# MDR1986VK214 register map
Vendor: Milandr; Series: ARMCM0; File version: 2.0
CPU: CM0 r0p0, little endian, no MPU, no FPU, 2 interrupt priority bits
Registers are 32-bit, read-write, reset 0x0 unless marked. A register's access mark holds for its fields unless they carry their own. Offsets are from the block's base; [hi:lo] are bit positions; {n}, {i} and the like mark numbered series; 'fields as' and 'values as' point back to an identical list.

## MDR_RST_CLOCK — CLock Control
Base 0x40020000
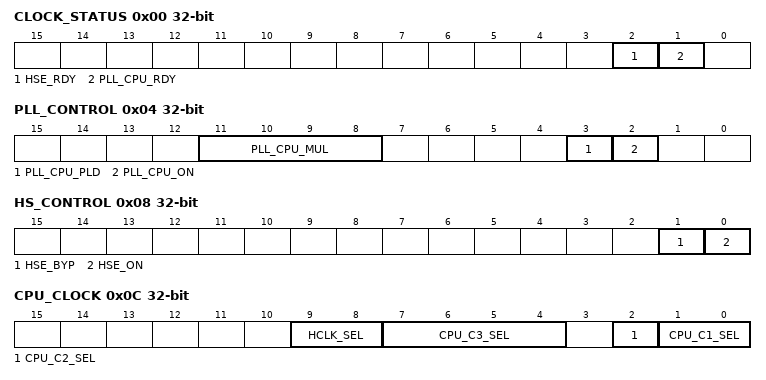
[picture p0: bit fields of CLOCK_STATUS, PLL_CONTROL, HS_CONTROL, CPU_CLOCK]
0x00 CLOCK_STATUS ro
  [2] HSE_RDY — HSE generator ready
    0=NotReady (HSE not ready); 1=Ready (HSE ready)
  [1] PLL_CPU_RDY — PLL CPU ready
    0=NotReady (PLL not ready); 1=Ready (PLL ready)
0x04 PLL_CONTROL (reset mask 0x20C)
  [11:8] PLL_CPU_MUL — PLL CPU Mul, [x1 .. x16]
    0=PLL mul x1; {v}=x{v+1} (PLL mul x{v+1}) (v=1..8); 9=PLL mul x10; 10=PLL mul x11; {v}=x{v+1} (PLL mul x{v+1}) (v=11..15)
  [3] PLL_CPU_PLD — PLL CPU Restart
    0=RestartOff (PLL restart inactive); 1=DoRestart (PLL Do Restart)
  [2] PLL_CPU_ON — PLL CPU Enable
    0=Off (PLL Off); 1=On (PLL On)
0x08 HS_CONTROL — HSE Generator Control
  [1] HSE_BYP — HSE Bypass Mode
    0=Off (HSE forms Clock from external oscillator); 1=On (HSE passes Clock from external generator)
  [0] HSE_ON — HSE Enable
    0=Off (HSE Off); 1=On (HSE On)
0x0C CPU_CLOCK — CPU Clock Control
  [9:8] HCLK_SEL — Select Clock for CPU
    0=HSI (CPU clock is HSI); 1=CPU_C3 (CPU clock is CPU_C3 output); 2=LSE (CPU clock is LSE); 3=LSI (CPU clock is LSI)
  [7:4] CPU_C3_SEL — CPU_C2 mux output freq devider, [/1, /2, /4 .. /256]
    0b0xxx=div1 (div by 1); 8=div2 (div by 2); 9=div4 (div by 4); 10=div8 (div by 8); 11=div16 (div by 16); 12=div32 (div by 32); 13=div64 (div by 64); 14=div128 (div by 128); 15=div256 (div by 256)
  [2] CPU_C2_SEL — CPU_C2 mux freq select
    0=CPU_C1 (Freq from CPU_C1 mux direct); 1=PLLCPUo (Freq from CPU_C1 mux through PLL)
  [1:0] CPU_C1_SEL — CPU_C1 mux freq select
    0=HSI (CPU_C1 output is HSI); 1=HSI/2 (CPU_C1 output is HSI/2); 2=HSE (CPU_C1 output is HSE); 3=HSE/2 (CPU_C1 output is HSE/2)
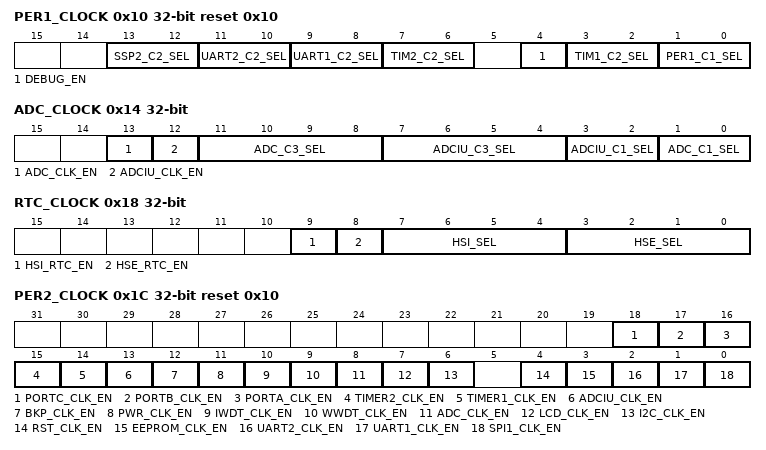
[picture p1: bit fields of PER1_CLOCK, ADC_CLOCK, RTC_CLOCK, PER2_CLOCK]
0x10 PER1_CLOCK reset 0x10 — Peripherials Clock Control1
  [13:12] SSP2_C2_SEL — SSP2_C2 mux freq select
    0=CPU_C1 (CPU_C1 clock selected); 1=PER1_C1 (PER1_C1 clock selected); 2=PLLCPUo clock selected; 3=HSI_C1 (HSI_C1 clock selected)
  [11:10] UART2_C2_SEL — UART2_C2 mux freq select
    values as SSP2_C2_SEL
  [9:8] UART1_C2_SEL — UART1_C2 mux freq select
    values as SSP2_C2_SEL
  [7:6] TIM2_C2_SEL — TIM2_C2 mux freq select
    values as SSP2_C2_SEL
  [4] DEBUG_EN — Debug clock enable
    0=Off (Debug disabled); 1=On (Debug enabled)
  [3:2] TIM1_C2_SEL — TIM1_C2 mux freq select
    values as SSP2_C2_SEL
  [1:0] PER1_C1_SEL — PER1_C1 mux freq select
    0=LSI (PER1_C1 output is LSI); 1=LSI/2 (PER1_C1 output is LSI/2); 2=LSE (PER1_C1 output is LSE); 3=LSE/2 (PER1_C1 output is LSE/2)
0x14 ADC_CLOCK (reset mask 0x3F33) — ADC Clock Control
  [13] ADC_CLK_EN — ADC Clock Enable
    0=Off (ADC clock disabled); 1=On (ADC clock enabled)
  [12] ADCIU_CLK_EN — ADCIU Clock Enable
    0=Off (ADCIU clock disabled); 1=On (ADCIU clock enabled)
  [11:8] ADC_C3_SEL — ADC_C1 mux output freq devider, [/1, /2, /4 .. /256]
    values as CPU_CLOCK.CPU_C3_SEL
  [7:4] ADCIU_C3_SEL — ADCIU_C1 mux output freq devider, [/1, /2, /4 .. /256]
    values as CPU_CLOCK.CPU_C3_SEL
  [3:2] ADCIU_C1_SEL — ADCIU_C1 mux freq select
    0=CPU_C1 (ADCIU_C1 output is CPU_C1); 1=PER1_C1 (ADCIU_C1 output is PER1_C1); 2=PLLCPUo (ADCIU_C1 output is PLLCPUo); 3=HSI_C1 (ADCIU_C1 output is HSI_C1)
  [1:0] ADC_C1_SEL — ADC_C1 mux freq select
    0=CPU_C1 (ADC_C1 output is CPU_C1); 1=PER1_C1 (ADC_C1 output is PER1_C1); 2=PLLCPUo (ADC_C1 output is PLLCPUo); 3=HSI_C1 (ADC_C1 output is HSI_C1)
0x18 RTC_CLOCK — RTC Clock Control
  [9] HSI_RTC_EN — RTC HSI Clock enable
    0=Off (RTC HSI Clock Disabled); 1=On (RTC HSI Clock Enabled)
  [8] HSE_RTC_EN — RTC HSE Clock enable
    0=Off (RTC HSE Clock Disabled); 1=On (RTC HSE Clock Enabled)
  [7:4] HSI_SEL — RTC HSI freq devider, [/1, /2, /4 .. /256]
    values as CPU_CLOCK.CPU_C3_SEL
  [3:0] HSE_SEL — RTC HSE freq devider, [/1, /2, /4 .. /256]
    values as CPU_CLOCK.CPU_C3_SEL
0x1C PER2_CLOCK reset 0x10 (reset mask 0x7FDFF) — Peripherials Clock Control 2
  [all] fields
    0=Off (Clock Disabled); 1=On (Clock Enabled)
  [18] PORTC_CLK_EN — GPIO PORT_C Clock Enable
  [17] PORTB_CLK_EN — GPIO PORT_B Clock Enable
  [16] PORTA_CLK_EN — GPIO PORT_A Clock Enable
  [15] TIMER2_CLK_EN — TIMER2 Clock Enable
  [14] TIMER1_CLK_EN — TIMER1 Clock Enable
  [13] ADCIU_CLK_EN — ADCIU Clock Enable
  [12] BKP_CLK_EN — Backup Clock Enable
  [11] PWR_CLK_EN — Power Clock Enable
  [10] IWDT_CLK_EN — IWDT Clock Enable
  [9] WWDT_CLK_EN — WWDT Clock Enable
  [8] ADC_CLK_EN — ADC Clock Enable
  [7] LCD_CLK_EN — LCD Clock Enable
  [6] I2C_CLK_EN — I2C Clock Enable
  [4] RST_CLK_EN — RST Clock Enable
  [3] EEPROM_CLK_EN — EEPROM Clock Enable
  [2] UART2_CLK_EN — UART2 Clock Enable
  [1] UART1_CLK_EN — UART1 Clock Enable
  [0] SPI1_CLK_EN — SPI1 Clock Enable
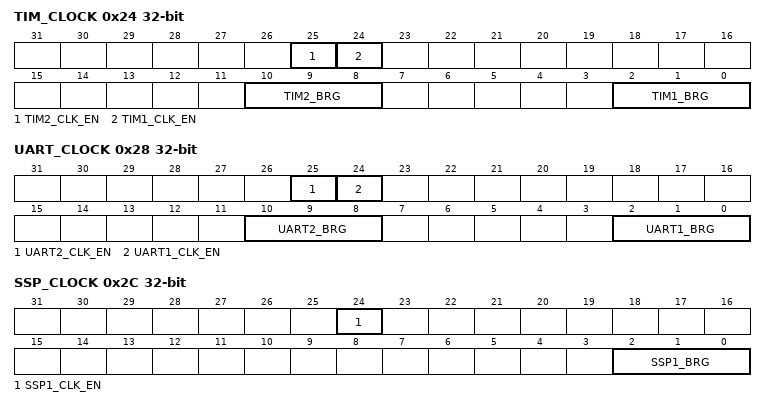
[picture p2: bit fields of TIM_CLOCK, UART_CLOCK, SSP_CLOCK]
0x24 TIM_CLOCK — Timer's Clock Control
  [25] TIM2_CLK_EN — TIM2_CLOCK enable
    0=Off (Timer2 Clock Disabled); 1=On (Timer2 Clock Enabled)
  [24] TIM1_CLK_EN — TIM1_CLOCK enable
    0=Off (Timer1 Clock Disabled); 1=On (Timer1 Clock Enabled)
  [10:8] TIM2_BRG — TIM2_C2 freq divider to get TIM2_CLOCK, [/1, /2, /4 .. /128]
    0=div1 (div by 1); 1=div2 (div by 2); 2=div4 (div by 4); 3=div8 (div by 8); 4=div16 (div by 16); 5=div32 (div by 32); 6=div64 (div by 64); 7=div128 (div by 128)
  [2:0] TIM1_BRG — TIM1_C2 freq divider to get TIM1_CLOCK, [/1, /2, /4 .. /128]
    values as TIM2_BRG
0x28 UART_CLOCK — UART's Clock Control
  [25] UART2_CLK_EN — UART2_CLOCK enable
    0=Off (UART2 Clock Disabled); 1=On (UART2 Clock Enabled)
  [24] UART1_CLK_EN — UART1_CLOCK enable
    0=Off (UART1 Clock Disabled); 1=On (UART1 Clock Enabled)
  [10:8] UART2_BRG — UART1_C2 freq divider to get UART2_CLOCK, [/1, /2, /4 .. /128]
    values as TIM_CLOCK.TIM2_BRG
  [2:0] UART1_BRG — UART1_C2 freq divider to get UART1_CLOCK, [/1, /2, /4 .. /128]
    values as TIM_CLOCK.TIM2_BRG
0x2C SSP_CLOCK — SSP's Clock Control
  [24] SSP1_CLK_EN — SSP1_CLOCK Enable
    0=Off (SSP1 Clock Disabled); 1=On (SSP1 Clock Enabled)
  [2:0] SSP1_BRG — SSP1_C2 freq divider to get SSP1_CLOCK, [/1, /2, /4 .. /128]
    values as TIM_CLOCK.TIM2_BRG
